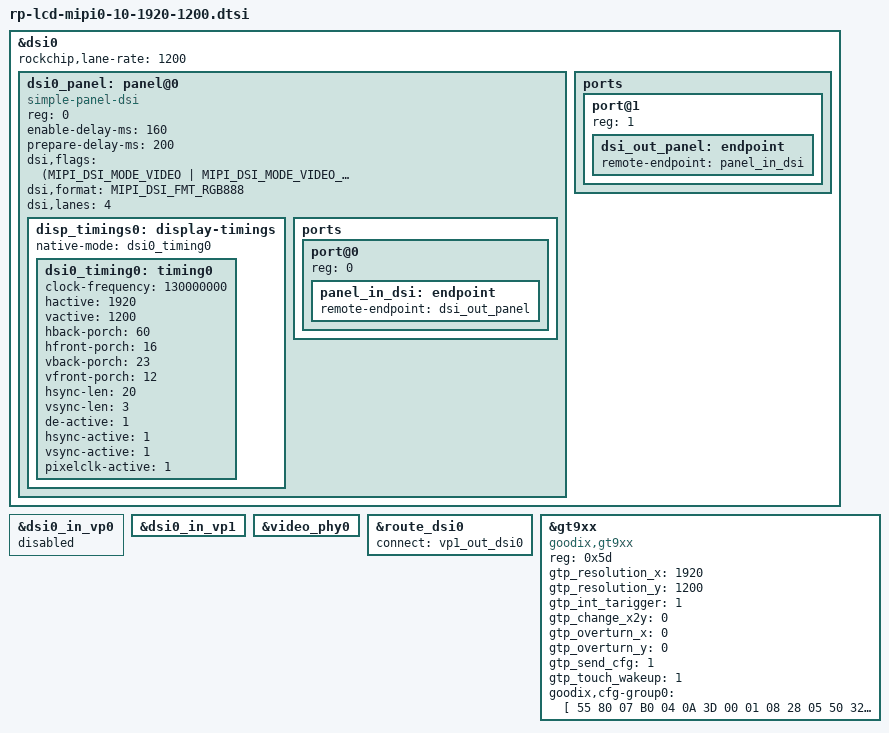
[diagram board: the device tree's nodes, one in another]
#include "rp-lcd-hdmi.dtsi"
#define RP_SINGLE_LCD





&dsi0 {
	status = "okay";
	rockchip,lane-rate = <1200>;
	dsi0_panel: panel@0 {
		status = "okay";
		compatible = "simple-panel-dsi";
		reg = <0>;
	//	reset-delay-ms = <60>;
	//	init-delay-ms = <60>;
		enable-delay-ms = <160>;
		prepare-delay-ms = <200>;
	//	unprepare-delay-ms = <60>;
	//	disable-delay-ms = <60>;
                dsi,flags = <(MIPI_DSI_MODE_VIDEO | MIPI_DSI_MODE_VIDEO_BURST |
                                MIPI_DSI_MODE_VIDEO_SYNC_PULSE)>;
                dsi,format = <MIPI_DSI_FMT_RGB888>;

		dsi,lanes  = <4>;
		
		/**
		 * power-supply = <>;
		 * reset-gpios = <>;
		 *
		 * lcd reset pin and power supply
		 * please refer to ***-lcd-gpio.dtsi
		 * that included in main dts.
		 */
		
		disp_timings0: display-timings {
			native-mode = <&dsi0_timing0>;
			dsi0_timing0: timing0 {
                                clock-frequency = <130000000>;
                                hactive = <1920>;
                                vactive = <1200>;
                                hback-porch = <60>;	//60
                                hfront-porch = <16>;	//16
                                vback-porch = <23>;	//23
                                vfront-porch = <12>;	//12
                                hsync-len = <20>;	//20
                                vsync-len = <3>;	//3
                                de-active = <1>;
                                hsync-active = <1>;
                                vsync-active = <1>;
                                pixelclk-active = <1>;

			};
		};

		ports {
			#address-cells = <1>;
			#size-cells = <0>;

			port@0 {
				reg = <0>;
				panel_in_dsi: endpoint {
					remote-endpoint = <&dsi_out_panel>;
				};
			};
		};
	};

	ports {
		#address-cells = <1>;
		#size-cells = <0>;

		port@1 {
			reg = <1>;
			dsi_out_panel: endpoint {
				remote-endpoint = <&panel_in_dsi>;
			};
		};
	};

};

&dsi0_in_vp0 {
	status = "disabled";
};

&dsi0_in_vp1 {
	status = "okay";
};

&video_phy0 {
	status = "okay";
};

&route_dsi0 {
	status = "okay";
	connect = <&vp1_out_dsi0>;
};


&gt9xx {
	status = "okay";
	compatible = "goodix,gt9xx";
	reg = <0x5d>;
	gtp_resolution_x = <1920>;
	gtp_resolution_y = <1200>;
	gtp_int_tarigger = <1>;
	gtp_change_x2y = <0>;
	gtp_overturn_x = <0>;
	gtp_overturn_y = <0>;
	gtp_send_cfg = <1>;
	gtp_touch_wakeup = <1>;

	/**
	 * goodix_rst_gpio = <>;
	 * goodix_irq_gpio = <>;
	 *
	 * touch panel interrupt and reset pin
	 * please refer to ***-lcd-gpio.dtsi
	 * that included in main dts.
	 */

	goodix,cfg-group0 = [
		55 80 07 B0 04 0A 3D 00 01 08 28
		05 50 32 03 05 00 00 00 00 00 00
		00 18 1A 1E 14 8E 2F 99 17 15 31
		0D 00 00 02 9B 03 1D 00 00 00 00
		00 00 00 00 00 00 00 1E 78 94 C5
		02 08 00 00 00 5B 22 00 4C 2D 00
		41 3C 00 38 4F 00 32 69 00 32 00
		00 00 00 00 00 00 00 00 00 00 00
		00 00 00 00 00 00 00 00 00 00 00
		00 00 00 00 00 00 00 00 00 00 00
		00 00 00 01 04 05 06 07 08 09 0C
		0D 0E 0F 10 11 14 15 16 17 FF FF
		00 00 00 00 00 00 00 00 00 00 00
		02 04 06 07 08 0A 0C 0D 0F 10 11
		12 13 19 1B 1C 1E 1F 20 21 22 23
		24 25 26 27 28 29 FF FF FF 00 00
		00 00 00 00 00 00 00 00 6B 01];
};
